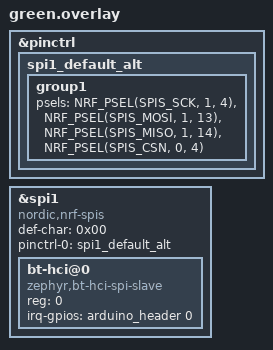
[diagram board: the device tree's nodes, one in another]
/*
 * Copyright (c) 2020 Nordic Semiconductor ASA
 *
 * SPDX-License-Identifier: Apache-2.0
 */

&pinctrl {
	spi1_default_alt: spi1_default_alt {
		group1 {
			psels = <NRF_PSEL(SPIS_SCK, 1, 4)>,
			        <NRF_PSEL(SPIS_MOSI, 1, 13)>,
			        <NRF_PSEL(SPIS_MISO, 1, 14)>,
			        <NRF_PSEL(SPIS_CSN, 0, 4)>;
		};
	};
};

&spi1 {
	compatible = "nordic,nrf-spis";
	status = "okay";
	def-char = <0x00>;
	pinctrl-0 = <&spi1_default_alt>;
	/delete-property/ pinctrl-1; // for low-power
	pinctrl-names = "default";

	bt-hci@0 {
		compatible = "zephyr,bt-hci-spi-slave";
		reg = <0>;
		irq-gpios = <&arduino_header 0 (GPIO_ACTIVE_HIGH | GPIO_PULL_DOWN)>;
	};
};
